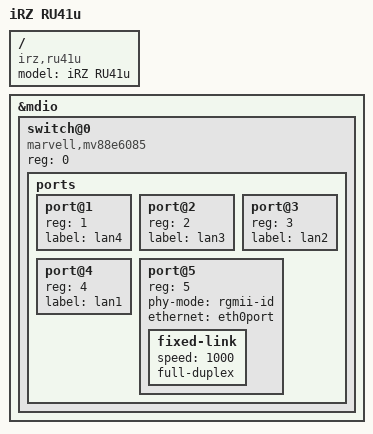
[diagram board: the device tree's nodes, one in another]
// SPDX-License-Identifier: GPL-2.0-or-later OR MIT

#include "kirkwood-irz_kw04.dts"

/ {
	model = "iRZ RU41u";
	compatible = "irz,ru41u", "irz,kw04", "marvell,kirkwood-88f6282", "marvell,kirkwood";
};

&mdio {

	status="okay";
	
	switch@0 {
		compatible = "marvell,mv88e6085";
		#address-cells = <1>;
		#size-cells = <0>;
		reg = <0>;
	
		ports {
			#address-cells = <1>;
			#size-cells = <0>;
		
			port@1 {
				reg = <1>;
				label = "lan4";
			};
		
			port@2 {
				reg = <2>;
				label = "lan3";
			};
		
			port@3 {
				reg = <3>;
				label = "lan2";
			};
		
			port@4 {
				reg = <4>;
				label = "lan1";
			};
		
			port@5 {
				reg = <5>;
				phy-mode = "rgmii-id";
				ethernet = <&eth0port>;
				fixed-link {
					speed = <1000>;
					full-duplex;
				};
			};
		};
	};
};
